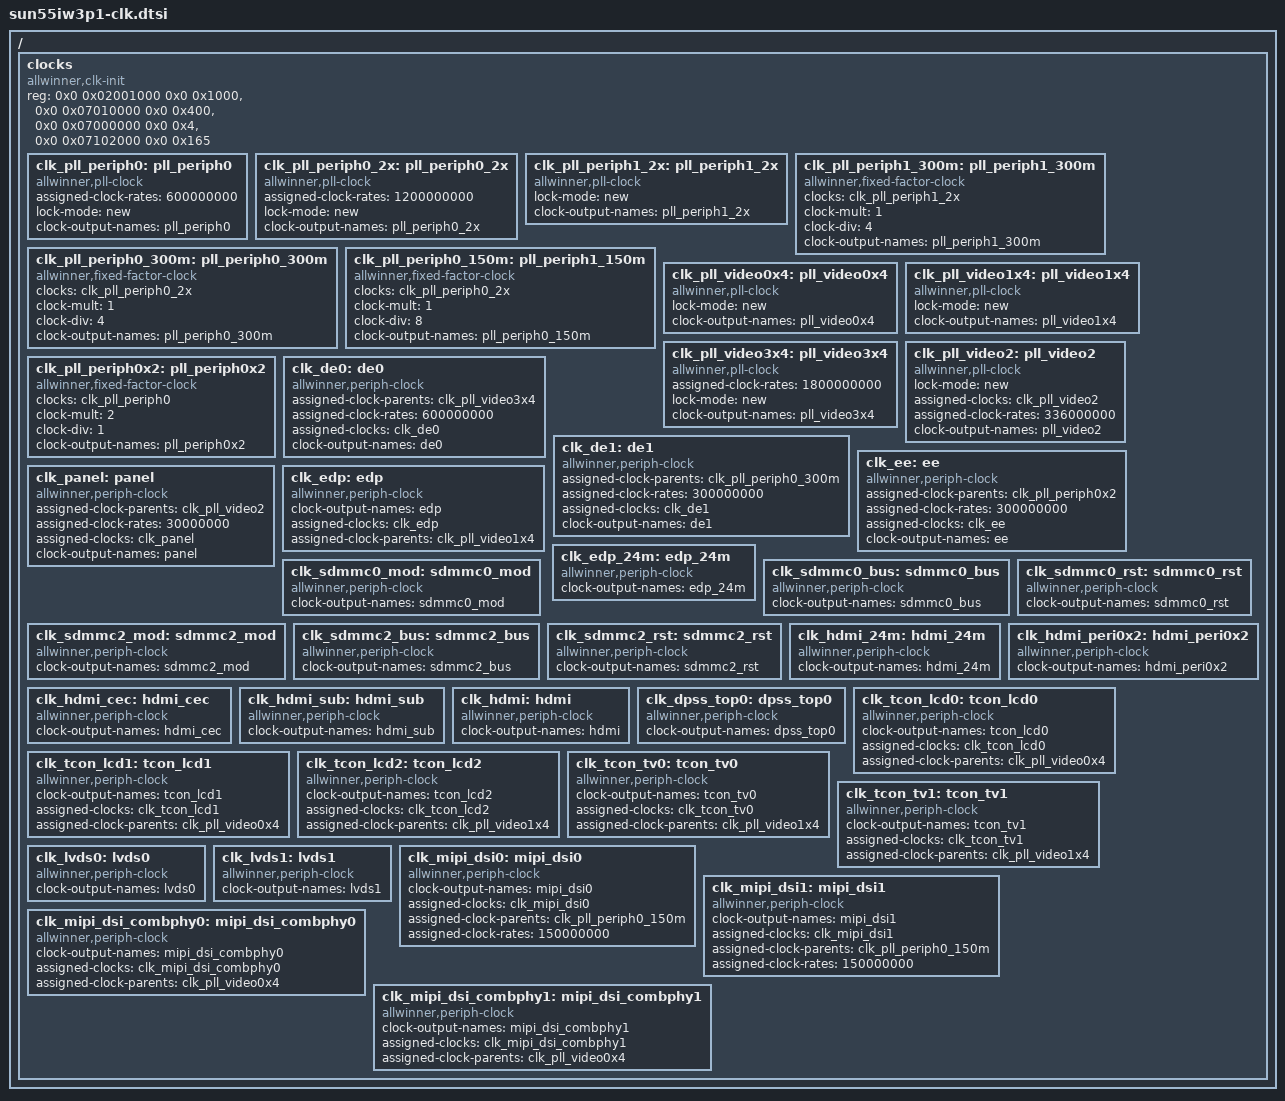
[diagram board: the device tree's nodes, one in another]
/{
clocks {
	compatible = "allwinner,clk-init";
	device_type = "clocks";
	#address-cells = <2>;
	#size-cells = <2>;
	ranges;
	reg = <0x0 0x02001000 0x0 0x1000>,	/*cpux space*/
	      <0x0 0x07010000 0x0 0x400>,	/*cpus space*/
	      <0x0 0x07000000 0x0 0x4>,
	      <0x0 0x07102000 0x0 0x165>;	/*dsp cpus space*/

		clk_pll_periph0: pll_periph0 {
			#clock-cells = <0>;
			compatible = "allwinner,pll-clock";
			assigned-clock-rates = <600000000>;
			lock-mode = "new";
			 clock-output-names = "pll_periph0";
		 };

		clk_pll_periph0_2x: pll_periph0_2x {
			#clock-cells = <0>;
			compatible = "allwinner,pll-clock";
			assigned-clock-rates = <1200000000>;
			lock-mode = "new";
			clock-output-names = "pll_periph0_2x";
		};
		clk_pll_periph1_2x: pll_periph1_2x {
			#clock-cells = <0>;
			compatible = "allwinner,pll-clock";
			lock-mode = "new";
			clock-output-names = "pll_periph1_2x";
		};

		clk_pll_periph1_300m: pll_periph1_300m {
			#clock-cells = <0>;
			compatible = "allwinner,fixed-factor-clock";
			clocks = <&clk_pll_periph1_2x>;
			clock-mult = <1>;
			clock-div = <4>;
			clock-output-names = "pll_periph1_300m";
		};

		clk_pll_periph0_300m: pll_periph0_300m {
			#clock-cells = <0>;
			compatible = "allwinner,fixed-factor-clock";
			clocks = <&clk_pll_periph0_2x>;
			clock-mult = <1>;
			clock-div = <4>;
			clock-output-names = "pll_periph0_300m";
		};

		clk_pll_periph0_150m: pll_periph1_150m {
			#clock-cells = <0>;
			compatible = "allwinner,fixed-factor-clock";
			clocks = <&clk_pll_periph0_2x>;
			clock-mult = <1>;
			clock-div = <8>;
			clock-output-names = "pll_periph0_150m";
		};
		clk_pll_video0x4: pll_video0x4 {
			#clock-cells = <0>;
			compatible = "allwinner,pll-clock";
			lock-mode = "new";
			clock-output-names = "pll_video0x4";
		};
		clk_pll_video1x4: pll_video1x4 {
			#clock-cells = <0>;
			compatible = "allwinner,pll-clock";
			lock-mode = "new";
			clock-output-names = "pll_video1x4";
		};
		clk_pll_video3x4: pll_video3x4 {
			#clock-cells = <0>;
			compatible = "allwinner,pll-clock";
			assigned-clock-rates = <1800000000>;
			lock-mode = "new";
			clock-output-names = "pll_video3x4";
		};
		clk_pll_video2: pll_video2 {
			#clock-cells = <0>;
			compatible = "allwinner,pll-clock";
			lock-mode = "new";
			assigned-clocks = <&clk_pll_video2>;
			assigned-clock-rates = <336000000>;
			clock-output-names = "pll_video2";
		};
		clk_pll_periph0x2: pll_periph0x2 {
			#clock-cells = <0>;
			compatible = "allwinner,fixed-factor-clock";
			clocks = <&clk_pll_periph0>;
			clock-mult = <2>;
			clock-div = <1>;
			clock-output-names = "pll_periph0x2";
		};
		clk_de0: de0 {
			#clock-cells = <0>;
			compatible = "allwinner,periph-clock";
			assigned-clock-parents = <&clk_pll_video3x4>;
			assigned-clock-rates = <600000000>;
			assigned-clocks = <&clk_de0>;
			clock-output-names = "de0";
		};
		clk_de1: de1 {
			#clock-cells = <0>;
			compatible = "allwinner,periph-clock";
			assigned-clock-parents = <&clk_pll_periph0_300m>;
			assigned-clock-rates = <300000000>;
			assigned-clocks = <&clk_de1>;
			clock-output-names = "de1";
		};
		clk_ee: ee {
			#clock-cells = <0>;
			compatible = "allwinner,periph-clock";
			assigned-clock-parents = <&clk_pll_periph0x2>;
			assigned-clock-rates = <300000000>;
			assigned-clocks = <&clk_ee>;
			clock-output-names = "ee";
		};
		clk_panel: panel {
			#clock-cells = <0>;
			compatible = "allwinner,periph-clock";
			assigned-clock-parents = <&clk_pll_video2>;
			assigned-clock-rates = <30000000>;
			assigned-clocks = <&clk_panel>;
			clock-output-names = "panel";
		};

		clk_edp: edp {
			#clock-cells = <0>;
			compatible = "allwinner,periph-clock";
			clock-output-names = "edp";
			assigned-clocks = <&clk_edp>;
			assigned-clock-parents = <&clk_pll_video1x4>;
		};

		clk_edp_24m: edp_24m {
			#clock-cells = <0>;
			compatible = "allwinner,periph-clock";
			clock-output-names = "edp_24m";
		};

		clk_sdmmc0_mod: sdmmc0_mod {
			#clock-cells = <0>;
			compatible = "allwinner,periph-clock";
			clock-output-names = "sdmmc0_mod";
		};
		clk_sdmmc0_bus: sdmmc0_bus {
			#clock-cells = <0>;
			compatible = "allwinner,periph-clock";
			clock-output-names = "sdmmc0_bus";
		};
		clk_sdmmc0_rst: sdmmc0_rst {
			#clock-cells = <0>;
			compatible = "allwinner,periph-clock";
			clock-output-names = "sdmmc0_rst";
		};
		clk_sdmmc2_mod: sdmmc2_mod {
			#clock-cells = <0>;
			compatible = "allwinner,periph-clock";
			clock-output-names = "sdmmc2_mod";
		};
		clk_sdmmc2_bus: sdmmc2_bus {
			#clock-cells = <0>;
			compatible = "allwinner,periph-clock";
			clock-output-names = "sdmmc2_bus";
		};
		clk_sdmmc2_rst: sdmmc2_rst {
			#clock-cells = <0>;
			compatible = "allwinner,periph-clock";
			clock-output-names = "sdmmc2_rst";
		};

		clk_hdmi_24m: hdmi_24m {
			#clock-cells = <0>;
			compatible = "allwinner,periph-clock";
			clock-output-names = "hdmi_24m";
		};
		clk_hdmi_peri0x2: hdmi_peri0x2 {
			#clock-cells = <0>;
			compatible = "allwinner,periph-clock";
			clock-output-names = "hdmi_peri0x2";
		};
		clk_hdmi_cec: hdmi_cec {
			#clock-cells = <0>;
			compatible = "allwinner,periph-clock";
			clock-output-names = "hdmi_cec";
		};

		clk_hdmi_sub: hdmi_sub {
			#clock-cells = <0>;
			compatible = "allwinner,periph-clock";
			clock-output-names = "hdmi_sub";
		};

		clk_hdmi: hdmi {
			#clock-cells = <0>;
			compatible = "allwinner,periph-clock";
			clock-output-names = "hdmi";
		};
		clk_dpss_top0: dpss_top0 {
			#clock-cells = <0>;
			compatible = "allwinner,periph-clock";
			clock-output-names = "dpss_top0";
		};
		clk_tcon_lcd0: tcon_lcd0 {
			#clock-cells = <0>;
			compatible = "allwinner,periph-clock";
			clock-output-names = "tcon_lcd0";
			assigned-clocks = <&clk_tcon_lcd0>;
			assigned-clock-parents = <&clk_pll_video0x4>;
		};
		clk_tcon_lcd1: tcon_lcd1 {
			#clock-cells = <0>;
			compatible = "allwinner,periph-clock";
			clock-output-names = "tcon_lcd1";
			assigned-clocks = <&clk_tcon_lcd1>;
			assigned-clock-parents = <&clk_pll_video0x4>;
		};
		clk_tcon_lcd2: tcon_lcd2 {
			#clock-cells = <0>;
			compatible = "allwinner,periph-clock";
			clock-output-names = "tcon_lcd2";
			assigned-clocks = <&clk_tcon_lcd2>;
			assigned-clock-parents = <&clk_pll_video1x4>;
		};
		clk_tcon_tv0: tcon_tv0 {
			#clock-cells = <0>;
			compatible = "allwinner,periph-clock";
			clock-output-names = "tcon_tv0";
			assigned-clocks = <&clk_tcon_tv0>;
			assigned-clock-parents = <&clk_pll_video1x4>;
		};
		clk_tcon_tv1: tcon_tv1 {
			#clock-cells = <0>;
			compatible = "allwinner,periph-clock";
			clock-output-names = "tcon_tv1";
			assigned-clocks = <&clk_tcon_tv1>;
			assigned-clock-parents = <&clk_pll_video1x4>;
		};
		clk_lvds0: lvds0 {
			#clock-cells = <0>;
			compatible = "allwinner,periph-clock";
			clock-output-names = "lvds0";
		};
		clk_lvds1: lvds1 {
			#clock-cells = <0>;
			compatible = "allwinner,periph-clock";
			clock-output-names = "lvds1";
		};
		clk_mipi_dsi0: mipi_dsi0 {
			#clock-cells = <0>;
			compatible = "allwinner,periph-clock";
			clock-output-names = "mipi_dsi0";
			assigned-clocks = <&clk_mipi_dsi0>;
			assigned-clock-parents = <&clk_pll_periph0_150m>;
			assigned-clock-rates = <150000000>;
		};
		clk_mipi_dsi1: mipi_dsi1 {
			#clock-cells = <0>;
			compatible = "allwinner,periph-clock";
			clock-output-names = "mipi_dsi1";
			assigned-clocks = <&clk_mipi_dsi1>;
			assigned-clock-parents = <&clk_pll_periph0_150m>;
			assigned-clock-rates = <150000000>;
		};
		clk_mipi_dsi_combphy0: mipi_dsi_combphy0 {
			#clock-cells = <0>;
			compatible = "allwinner,periph-clock";
			clock-output-names = "mipi_dsi_combphy0";
			assigned-clocks = <&clk_mipi_dsi_combphy0>;
			assigned-clock-parents = <&clk_pll_video0x4>;
		};
		clk_mipi_dsi_combphy1: mipi_dsi_combphy1 {
			#clock-cells = <0>;
			compatible = "allwinner,periph-clock";
			clock-output-names = "mipi_dsi_combphy1";
			assigned-clocks = <&clk_mipi_dsi_combphy1>;
			assigned-clock-parents = <&clk_pll_video0x4>;
		};
	};
};
